AUTOSAR XML (schema 4-2-2)
package /Components
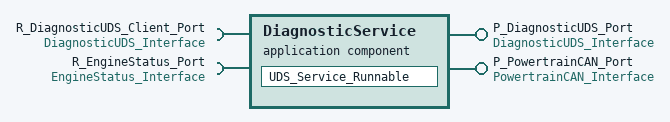
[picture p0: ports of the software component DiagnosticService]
  application sw component type DiagnosticService
    provide port P_DiagnosticUDS_Port: provided-interface=DiagnosticUDS_Interface
    provide port P_PowertrainCAN_Port: provided-interface=PowertrainCAN_Interface
    require port R_DiagnosticUDS_Client_Port: required-interface=DiagnosticUDS_Interface
    require port R_EngineStatus_Port: required-interface=EngineStatus_Interface
    behavior DiagnosticServiceBehavior
      data received event Component_Diagnostic_Event: start-on-event=Routing_Process_Runnable
      operation invoked event UDS_Request_Event: start-on-event=Routing_Process_Runnable, operation=P_DiagnosticUDS_Port.HandleUDSRequest
      runnable UDS_Service_Runnable: minimum-start-interval=50, symbol=DiagnosticService_UDS_Runnable
        data-receive-point-by-arguments:
          access EngineStatus_Access: accessed-variable=R_EngineStatus_Port.EngineStatus
          access UDS_Request_Argument: accessed-variable=R_DiagnosticUDS_Client_Port.UDS_Request
        sync call ReadDTC_Call: operation=R_DiagnosticUDS_Client_Port.ReadDTC, timeout=100
        sync call ClearDTC_Call: operation=R_DiagnosticUDS_Client_Port.ClearDTC, timeout=200
